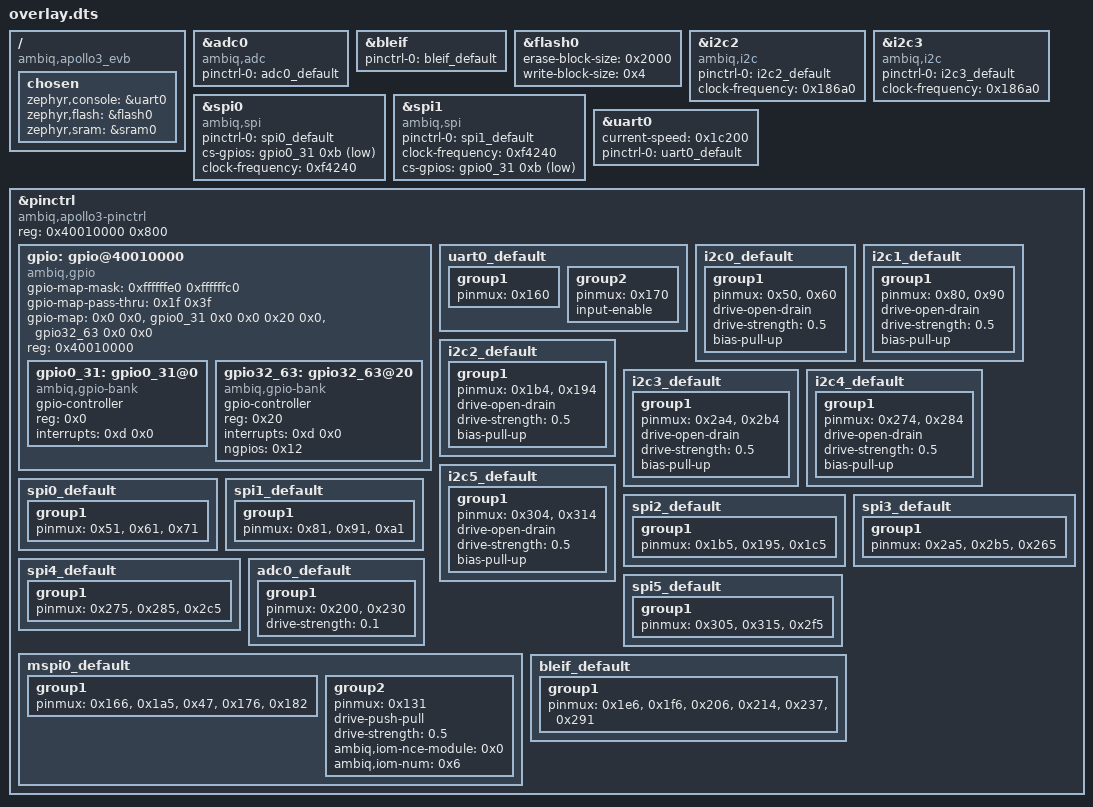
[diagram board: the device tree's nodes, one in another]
/ {
	compatible = "ambiq,apollo3_evb";
	chosen {
		zephyr,console = &uart0;
		zephyr,flash = &flash0;
		zephyr,sram = &sram0;
	};
};
&adc0{
	compatible = "ambiq,adc";
	pinctrl-0 = < &adc0_default >;
	pinctrl-names = "default";
};
&bleif{
	status = "okay";
	pinctrl-0 = < &bleif_default >;
	pinctrl-names = "default";
};
&flash0{
	erase-block-size = < 0x2000 >;
	write-block-size = < 0x4 >;
};
&gpio0_31{
	status = "okay";
};
&gpio32_63{
	status = "okay";
};
&i2c2{
	status = "okay";
	compatible = "ambiq,i2c";
	pinctrl-0 = < &i2c2_default >;
	pinctrl-names = "default";
	clock-frequency = < 0x186a0 >;
};
&i2c3{
	status = "okay";
	compatible = "ambiq,i2c";
	pinctrl-0 = < &i2c3_default >;
	pinctrl-names = "default";
	clock-frequency = < 0x186a0 >;
};
&spi0{
	status = "okay";
	compatible = "ambiq,spi";
	pinctrl-0 = < &spi0_default >;
	pinctrl-names = "default";
	cs-gpios = < &gpio0_31 0xb 0x1 >;
	clock-frequency = < 0xf4240 >;
};
&spi1{
	status = "okay";
	compatible = "ambiq,spi";
	pinctrl-0 = < &spi1_default >;
	pinctrl-names = "default";
	clock-frequency = < 0xf4240 >;
	cs-gpios = < &gpio0_31 0xb 0x1 >;
};
&uart0{
	status = "okay";
	current-speed = < 0x1c200 >;
	pinctrl-0 = < &uart0_default >;
	pinctrl-names = "default";
};
&pinctrl{
	compatible = "ambiq,apollo3-pinctrl";
	reg = < 0x40010000 0x800 >;
	#address-cells = < 0x1 >;
	#size-cells = < 0x0 >;
	gpio: gpio@40010000 {
		compatible = "ambiq,gpio";
		gpio-map-mask = < 0xffffffe0 0xffffffc0 >;
		gpio-map-pass-thru = < 0x1f 0x3f >;
		gpio-map = < 0x0 0x0 &gpio0_31 0x0 0x0 0x20 0x0 &gpio32_63 0x0 0x0 >;
		reg = < 0x40010000 >;
		#gpio-cells = < 0x2 >;
		#address-cells = < 0x1 >;
		#size-cells = < 0x0 >;
		ranges;
		gpio0_31: gpio0_31@0 {
			compatible = "ambiq,gpio-bank";
			gpio-controller;
			#gpio-cells = < 0x2 >;
			reg = < 0x0 >;
			interrupts = < 0xd 0x0 >;
			status = "okay";
			phandle = < 0x6 >;
		};
		gpio32_63: gpio32_63@20 {
			compatible = "ambiq,gpio-bank";
			gpio-controller;
			#gpio-cells = < 0x2 >;
			reg = < 0x20 >;
			interrupts = < 0xd 0x0 >;
			status = "okay";
			ngpios = < 0x12 >;
			phandle = < 0xa >;
		};
	};
	uart0_default: uart0_default {
		group1 {
			pinmux = < 0x160 >;
		};
		group2 {
			pinmux = < 0x170 >;
			input-enable;
		};
	};
	i2c0_default: i2c0_default {
		group1 {
			pinmux = < 0x50 >, < 0x60 >;
			drive-open-drain;
			drive-strength = "0.5";
			bias-pull-up;
		};
	};
	i2c1_default: i2c1_default {
		group1 {
			pinmux = < 0x80 >, < 0x90 >;
			drive-open-drain;
			drive-strength = "0.5";
			bias-pull-up;
		};
	};
	i2c2_default: i2c2_default {
		group1 {
			pinmux = < 0x1b4 >, < 0x194 >;
			drive-open-drain;
			drive-strength = "0.5";
			bias-pull-up;
		};
	};
	i2c3_default: i2c3_default {
		group1 {
			pinmux = < 0x2a4 >, < 0x2b4 >;
			drive-open-drain;
			drive-strength = "0.5";
			bias-pull-up;
		};
	};
	i2c4_default: i2c4_default {
		group1 {
			pinmux = < 0x274 >, < 0x284 >;
			drive-open-drain;
			drive-strength = "0.5";
			bias-pull-up;
		};
	};
	i2c5_default: i2c5_default {
		group1 {
			pinmux = < 0x304 >, < 0x314 >;
			drive-open-drain;
			drive-strength = "0.5";
			bias-pull-up;
		};
	};
	spi0_default: spi0_default {
		group1 {
			pinmux = < 0x51 >, < 0x61 >, < 0x71 >;
		};
	};
	spi1_default: spi1_default {
		group1 {
			pinmux = < 0x81 >, < 0x91 >, < 0xa1 >;
		};
	};
	spi2_default: spi2_default {
		group1 {
			pinmux = < 0x1b5 >, < 0x195 >, < 0x1c5 >;
		};
	};
	spi3_default: spi3_default {
		group1 {
			pinmux = < 0x2a5 >, < 0x2b5 >, < 0x265 >;
		};
	};
	spi4_default: spi4_default {
		group1 {
			pinmux = < 0x275 >, < 0x285 >, < 0x2c5 >;
		};
	};
	spi5_default: spi5_default {
		group1 {
			pinmux = < 0x305 >, < 0x315 >, < 0x2f5 >;
		};
	};
	adc0_default: adc0_default {
		group1 {
			pinmux = < 0x200 >, < 0x230 >;
			drive-strength = "0.1";
		};
	};
	mspi0_default: mspi0_default {
		group1 {
			pinmux = < 0x166 >, < 0x1a5 >, < 0x47 >, < 0x176 >, < 0x182 >;
		};
		group2 {
			pinmux = < 0x131 >;
			drive-push-pull;
			drive-strength = "0.5";
			ambiq,iom-nce-module = < 0x0 >;
			ambiq,iom-num = < 0x6 >;
		};
	};
	bleif_default: bleif_default {
		group1 {
			pinmux = < 0x1e6 >, < 0x1f6 >, < 0x206 >, < 0x214 >, < 0x237 >, < 0x291 >;
		};
	};
};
